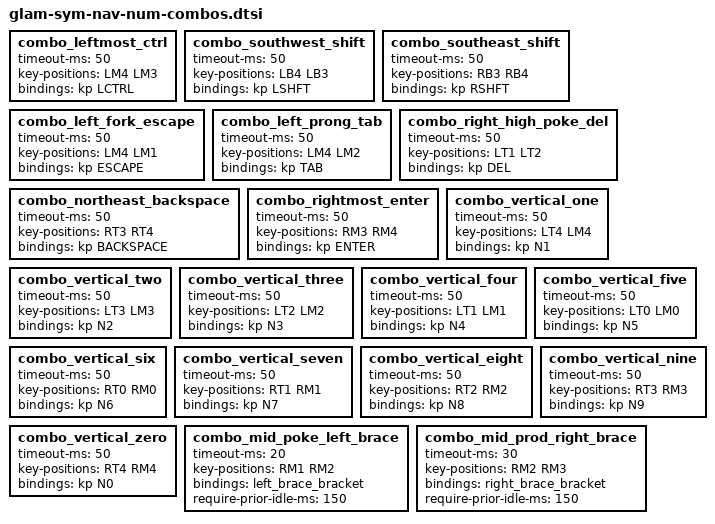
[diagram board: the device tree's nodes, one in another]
/*
 * Copyright (c) 2024 Allister MacLeod
 *
 * SPDX-License-Identifier: MIT
 */

// Shared combos for my 36-key (Corne) and 34-key (Zaphod, Sweep)
// keymaps. This includes combos for numbers, modifiers, and navigation
// keys since I want those to be consistent across boards. However, I
// have left the digraph and multi-letter sequence combos in the
// individual keymaps since those are specific to the alpha layer layout
// which may vary from board to board, as well as meta stuff like
// getting to the keyboard control layer. Some of the symbol combo
// bindings require behaviors to be defined in the keymap.

// REQUIRES (from glam-util.dtsi):
//  - &left_brace_bracket
//  - &right_brace_bracket
//  - &left_paren_angle
//  - &right_paren_angle

// This file is meant to be included in the middle of a `combos` block.

// combos {

  // Chord combos for modifiers and special keys:
  // Left pinky and ring in middle row for LCtrl.
  combo_leftmost_ctrl {
    timeout-ms = <50>;
    key-positions = <LM4 LM3>;
    bindings = <&kp LCTRL>;
  };
  // Left pinky and ring in bottom row for LShift.
  combo_southwest_shift {
    timeout-ms = <50>;
    key-positions = <LB4 LB3>;
    bindings = <&kp LSHFT>;
  };
  // Right pinky and ring in bottom row for RShift.
  combo_southeast_shift {
    timeout-ms = <50>;
    key-positions = <RB3 RB4>;
    bindings = <&kp RSHFT>;
  };
  // Left pinky and index in middle row for Esc.
  combo_left_fork_escape {
    timeout-ms = <50>;
    key-positions = <LM4 LM1>;
    bindings = <&kp ESCAPE>;
  };
  // Left pinky and middle finger in middle row for Tab.
  combo_left_prong_tab {
    timeout-ms = <50>;
    key-positions = <LM4 LM2>;
    bindings = <&kp TAB>;
  };
  // Right index and middle in top row for Delete.
  combo_right_high_poke_del {
    timeout-ms = <50>;
    key-positions = <LT1 LT2>;
    bindings = <&kp DEL>;
  };
  // Right pinky and ring in top row for Backspace.
  combo_northeast_backspace {
    timeout-ms = <50>;
    key-positions = <RT3 RT4>;
    bindings = <&kp BACKSPACE>;
  };
  // Right pinky and ring in middle row for Enter.
  combo_rightmost_enter {
    timeout-ms = <50>;
    key-positions = <RM3 RM4>;
    bindings = <&kp ENTER>;
  };
  // Vertical combos for numbers.
  combo_vertical_one {
    timeout-ms = <50>;
    key-positions = <LT4 LM4>;
    bindings = <&kp N1>;
  };
  combo_vertical_two {
    timeout-ms = <50>;
    key-positions = <LT3 LM3>;
    bindings = <&kp N2>;
  };
  combo_vertical_three {
    timeout-ms = <50>;
    key-positions = <LT2 LM2>;
    bindings = <&kp N3>;
  };
  combo_vertical_four {
    timeout-ms = <50>;
    key-positions = <LT1 LM1>;
    bindings = <&kp N4>;
  };
  combo_vertical_five {
    timeout-ms = <50>;
    key-positions = <LT0 LM0>;
    bindings = <&kp N5>;
  };
  combo_vertical_six {
    timeout-ms = <50>;
    key-positions = <RT0 RM0>;
    bindings = <&kp N6>;
  };
  combo_vertical_seven {
    timeout-ms = <50>;
    key-positions = <RT1 RM1>;
    bindings = <&kp N7>;
  };
  combo_vertical_eight {
    timeout-ms = <50>;
    key-positions = <RT2 RM2>;
    bindings = <&kp N8>;
  };
  combo_vertical_nine {
    timeout-ms = <50>;
    key-positions = <RT3 RM3>;
    bindings = <&kp N9>;
  };
  combo_vertical_zero {
    timeout-ms = <50>;
    key-positions = <RT4 RM4>;
    bindings = <&kp N0>;
  };
  // Right hand combos for symbols and stuff. These ought not to
  // interfere with Hands Down Neu multigraph combos, since those are
  // mostly on the left hand (with Qu being the notable exception).
  // Right index and ring in middle row for left brace and bracket.
  // This is E and A in Hands Down Neu, so it needs some roll protection because of the EA and AE diphthongs.
  combo_mid_poke_left_brace {
    timeout-ms = <20>;
    key-positions = <RM1 RM2>;
    bindings = <&left_brace_bracket>;
    require-prior-idle-ms = <150>;
  };
  // Right middle and ring in middle row for right brace and bracket.
  // This is I and E in Hands Down Neu, so it needs a little roll protection because of the IE diphthong.
  combo_mid_prod_right_brace {
    timeout-ms = <30>;
    key-positions = <RM2 RM3>;
    bindings = <&right_brace_bracket>;
    require-prior-idle-ms = <150>;
  };

// };
